AUTOSAR XML (schema 4-2-2)
package /ComponentTypes
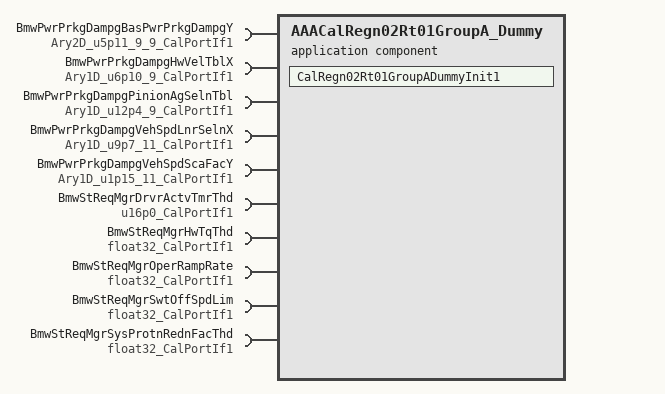
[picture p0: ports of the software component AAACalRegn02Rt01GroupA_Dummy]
  application sw component type AAACalRegn02Rt01GroupA_Dummy
    10 x require port:
      BmwPwrPrkgDampgBasPwrPrkgDampgY: parameter-require-com-spec{init-value=[[0, 0, 0, 0, 205, 410, 614, 819, 1024], [0, 0, 0, 0, 205, 410, 614, 819, 1024], [0, 0, 0, 0, 205, 410, 614, 819, 1024], [0, 0, 0, 0, 205, 410, 614, 819, 1024], [0, 0, 0, 0, 205, 410, 614, 819, 1024], [0, 0, 0, 0, 205, 410, 614, 819, 1024], [0, 0, 0, 0, 205, 410, 614, 819, 1024], [0, 0, 0, 0, 154, 307, 471, 604, 819], [0, 0, 0, 0, 20, 41, 61, 82, 102]], parameter=Ary2D}, required-interface=Ary2D_u5p11_9_9_CalPortIf1
      BmwPwrPrkgDampgHwVelTblX: parameter-require-com-spec{init-value=[0, 1280, 2560, 3840, 5120, 6400, 7680, 8960, 10240], parameter=Ary1D}, required-interface=Ary1D_u6p10_9_CalPortIf1
      BmwPwrPrkgDampgPinionAgSelnTbl: parameter-require-com-spec{init-value=[0, 1200, 2400, 3600, 4800, 6000, 7200, 8400, 9600], parameter=Ary1D}, required-interface=Ary1D_u12p4_9_CalPortIf1
      BmwPwrPrkgDampgVehSpdLnrSelnX: parameter-require-com-spec{init-value=[0, 256, 512, 768, 1024, 1280, 1536, 1792, 2048, 2304, 2560], parameter=Ary1D}, required-interface=Ary1D_u9p7_11_CalPortIf1
      BmwPwrPrkgDampgVehSpdScaFacY: parameter-require-com-spec{init-value=[32768, 32768, 32768, 32768, 32768, 32768, 26214, 19661, 13107, 6554, 0], parameter=Ary1D}, required-interface=Ary1D_u1p15_11_CalPortIf1
      BmwStReqMgrDrvrActvTmrThd: parameter-require-com-spec{init-value=500, parameter=Val}, required-interface=u16p0_CalPortIf1
      BmwStReqMgrHwTqThd: parameter-require-com-spec{init-value=0.4, parameter=Val}, required-interface=float32_CalPortIf1
      BmwStReqMgrOperRampRate: parameter-require-com-spec{init-value=1, parameter=Val}, required-interface=float32_CalPortIf1
      BmwStReqMgrSwtOffSpdLim: parameter-require-com-spec{init-value=10, parameter=Val}, required-interface=float32_CalPortIf1
      BmwStReqMgrSysProtnRednFacThd: parameter-require-com-spec{init-value=0.3, parameter=Val}, required-interface=float32_CalPortIf1
    behavior AAACalRegn02Rt01GroupA_Dummy_InternalBehavior: supports-multiple-instantiation=true
      init event AAACalRegn02Rt01GroupA_Dummy_InitEvent: start-on-event=CalRegn02Rt01GroupADummyInit1
      runnable CalRegn02Rt01GroupADummyInit1
  swc implementation AAACalRegn02Rt00GroupA_Dummy_Implementation: behavior=AAACalRegn02Rt01GroupA_Dummy_InternalBehavior
    code-descriptors:
      code Default: artifact-descriptors=autosar-engineering-object={short-label=Default, category=SWSRC}
